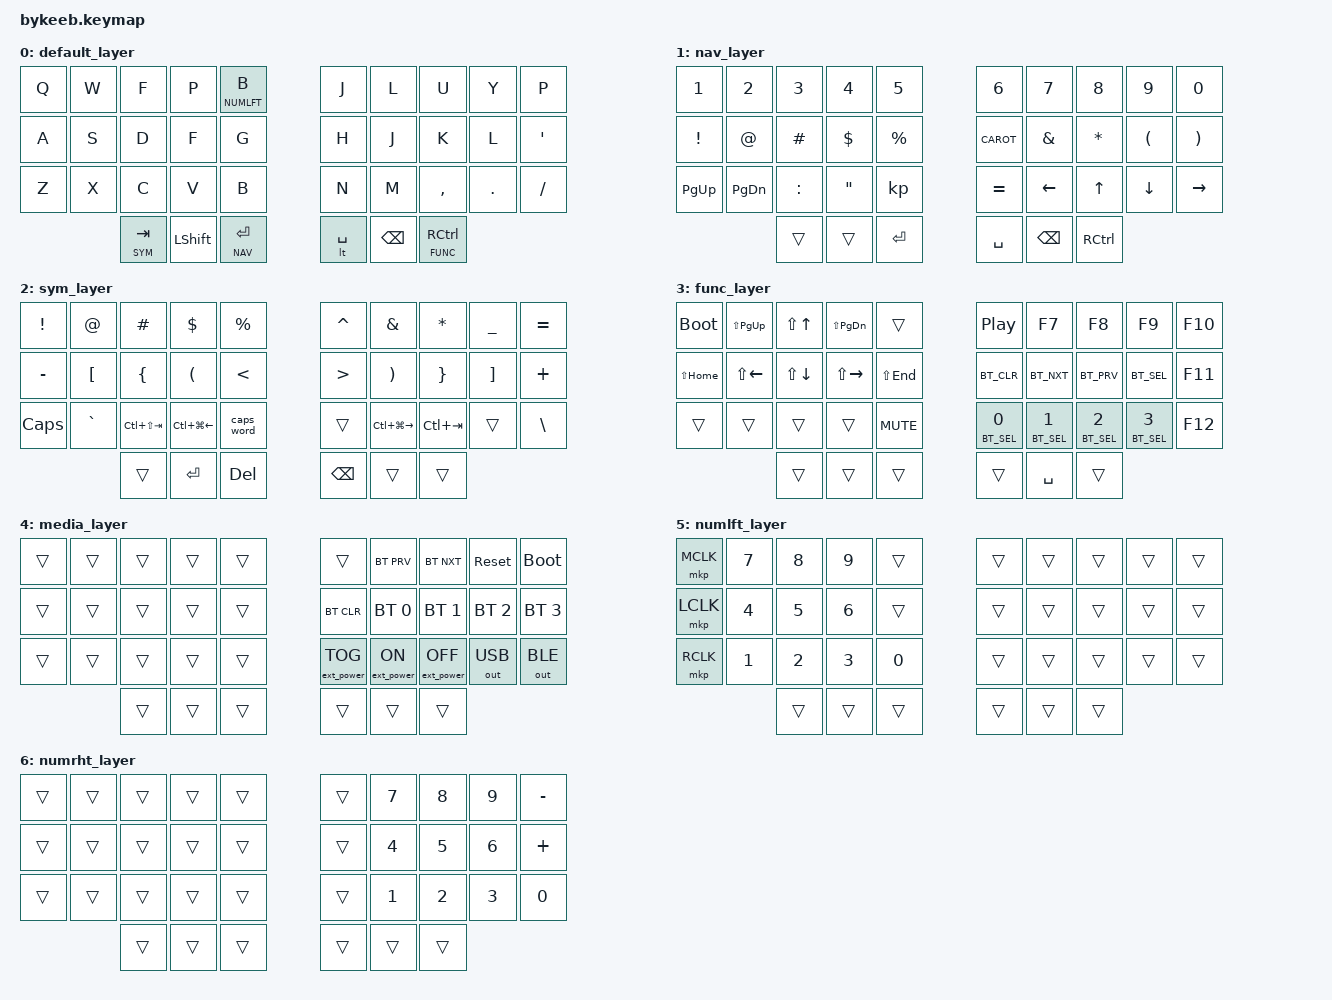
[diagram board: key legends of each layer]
/*
 * Copyright (c) 2020 The ZMK Contributors
 *
 * SPDX-License-Identifier: MIT
 */

 #include <behaviors.dtsi>
 #include <dt-bindings/zmk/keys.h>
 #include <dt-bindings/zmk/bt.h>
 #include <dt-bindings/zmk/ext_power.h>
 #include <dt-bindings/zmk/outputs.h>
 #include <dt-bindings/zmk/mouse.h>
 #include <behaviors/mouse_keys.dtsi>
 
 #define DEFAULT 0
 #define NAV     1
 #define SYM     2
 #define FUNC    3
 #define MEDIA   4
 #define NUMLFT  5
 #define NUMRHT  6
 
&caps_word {
     continue-list = <UNDERSCORE MINUS>;
 };
 
 / {
     combos {
         compatible = "zmk,combos";
         combo_undo {
             timeout-ms = <50>;
             key-positions = <20 21>;
             bindings = <&kp LC(Z)>;
         };
     };
 };
 
 / {
     behaviors {
         {
             compatible = "zmk,behavior-hold-tap";
             #binding-cells = <2>;
             tapping-term-ms = <200>;
             flavor = "tap-preferred";
             bindings = <&kp>, <&kp>;
         };
         hs: homerow_shift {
             compatible = "zmk,behavior-hold-tap";
             #binding-cells = <2>;
             tapping-term-ms = <175>;
             flavor = "balanced";
             bindings = <&kp>, <&kp>;
         };
     };
 
     keymap {
         compatible = "zmk,keymap";
 
         default_layer {
             bindings = <
     &kp Q        &kp W        &kp F       &kp P         &lt NUMLFT B                                &kp J  &kp L        &kp U         &kp Y       &kp P
     &kp A   &kp S   &kp D  &kp F  &kp G                                       &kp H         &kp J &kp K    &kp L  &kp APOS
     &kp Z        &kp X        &kp C       &kp V         &kp B                                       &kp N         &kp M        &kp COMMA     &kp DOT     &kp FSLH
                                           &lt SYM TAB       &kp LSHIFT  &lt NAV ENTER      &lt SPACE   &kp BSPC  &lt FUNC RCTRL
             >;
         };
 
         nav_layer {
             bindings = <
     &kp N1      &kp N2    &kp N3     &kp N4    &kp N5                                       &kp N6     &kp N7       &kp N8        &kp N9      &kp N0
     &kp EXCL     &kp AT     &kp HASH    &kp DLLR     &kp PRCNT                                    &kp CAROT      &kp AMPS       &kp ASTRK       &kp LPAR      &kp RPAR
     &kp PG_UP       &kp PG_DN       &kp COLON      &kp DQT      &kp                                       &kp EQUAL     &kp LEFT       &kp UP        &kp DOWN      &kp RIGHT
                                           &trans        &trans       &kp ENTER       &kp SPACE        &kp BSPC     &kp RCTRL
             >;
         };
 
         sym_layer {
             bindings = <
     &kp EXCL     &kp AT       &kp HASH        &kp DLLR         &kp PRCNT                                   &kp CARET     &kp AMPS          &kp ASTRK     &kp UNDER   &kp EQUAL
     &kp MINUS    &kp LBKT     &kp LBRC        &kp LPAR         &kp LT                                      &kp GT        &kp RPAR          &kp RBRC      &kp RBKT    &kp PLUS
     &kp CAPS     &kp GRAVE    &kp LC(LS(TAB)) &kp LC(LG(LEFT)) &caps_word                                  &trans        &kp LC(LG(RIGHT)) &kp LC(TAB)   &trans      &kp BSLH
                                               &trans           &kp RET       &kp DEL        &kp BSPC       &trans        &trans
             >;
         };
 
         func_layer {
             bindings = <
     &bootloader  &kp LS(PG_UP) &kp LS(UP)   &kp LS(PG_DN) &trans                                      &kp C_PLAY_PAUSE &kp F7       &kp F8        &kp F9      &kp F10
     &kp LS(HOME) &kp LS(LEFT)  &kp LS(DOWN) &kp LS(RIGHT) &kp LS(END)                                 &BT_CLR     &BT_NXT      &BT_PRV        &BT_SEL  &kp F11
     &trans       &trans        &trans       &trans        &kp C_MUTE                                  &BT_SEL 0     &BT_SEL 1      &BT_SEL 2      &BT_SEL 3     &kp F12
                                             &trans        &trans        &trans       &trans           &kp SPACE        &trans
             >;
         };
 
         media_layer {
             bindings = <
     &trans       &trans        &trans       &trans        &trans                                     &trans             &bt BT_PRV        &bt BT_NXT         &sys_reset     &bootloader
     &trans       &trans        &trans       &trans        &trans                                     &bt BT_CLR         &bt BT_SEL 0      &bt BT_SEL 1       &bt BT_SEL 2   &bt BT_SEL 3
     &trans       &trans        &trans       &trans        &trans                                     &ext_power EP_TOG  &ext_power EP_ON  &ext_power EP_OFF  &out OUT_USB   &out OUT_BLE
                                             &trans        &trans        &trans        &trans         &trans             &trans
             >;
         };
 
         numlft_layer {
             bindings = <
     &mkp MCLK    &kp N7       &kp N8       &kp N9        &trans                                      &trans      &trans      &trans      &trans      &trans
     &mkp LCLK    &kp N4       &kp N5       &kp N6        &trans                                      &trans      &trans      &trans      &trans      &trans
     &mkp RCLK    &kp N1       &kp N2       &kp N3        &kp N0                                      &trans      &trans      &trans      &trans      &trans
                                            &trans        &trans        &trans         &trans         &trans      &trans
             >;
         };

         numrht_layer {
            bindings = <
                &trans       &trans       &trans       &trans        &trans                                      &trans      &kp N7       &kp N8        &kp N9      &kp MINUS
                &trans       &trans       &trans       &trans        &trans                                      &trans      &kp N4       &kp N5        &kp N6      &kp PLUS
                &trans       &trans       &trans       &trans        &trans                                      &trans      &kp N1       &kp N2        &kp N3      &kp N0
                                                    &trans        &trans        &trans         &trans         &trans      &trans
            >;
        };
     };
 };
 
